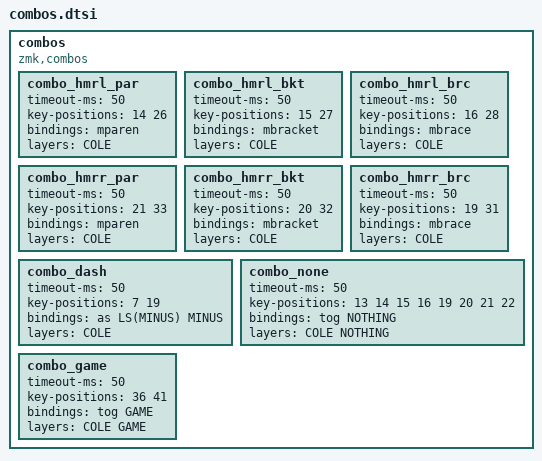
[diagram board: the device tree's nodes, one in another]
combos {

    compatible = "zmk,combos";

    /* #include "combo_shift.dtsi" */

    combo_hmrl_par {
        timeout-ms = <50>;
        key-positions = <14 26>;
        bindings = <&mparen>;
        layers = <COLE>;
    };

    combo_hmrl_bkt {
        timeout-ms = <50>;
        key-positions = <15 27>;
        bindings = <&mbracket>;
        layers = <COLE>;
    };

    combo_hmrl_brc {
        timeout-ms = <50>;
        key-positions = <16 28>;
        bindings = <&mbrace>;
        layers = <COLE>;
    };

    combo_hmrr_par {
        timeout-ms = <50>;
        key-positions = <21 33>;
        bindings = <&mparen>;
        layers = <COLE>;
    };

    combo_hmrr_bkt {
        timeout-ms = <50>;
        key-positions = <20 32>;
        bindings = <&mbracket>;
        layers = <COLE>;
    };

    combo_hmrr_brc {
        timeout-ms = <50>;
        key-positions = <19 31>;
        bindings = <&mbrace>;
        layers = <COLE>;
    };

    combo_dash {
        timeout-ms = <50>;
        key-positions = <7 19>;
        bindings = <&as LS(MINUS) MINUS>;
        layers = <COLE>;
    };

    combo_none {
        timeout-ms = <50>;
        key-positions = <13 14 15 16 19 20 21 22>;
        bindings = <&tog NOTHING>;
        layers = <COLE NOTHING>;
    };

    combo_game {
        timeout-ms = <50>;
        key-positions = <36 41>;
        bindings = <&tog GAME>;
        layers = <COLE GAME>;
    };

};
